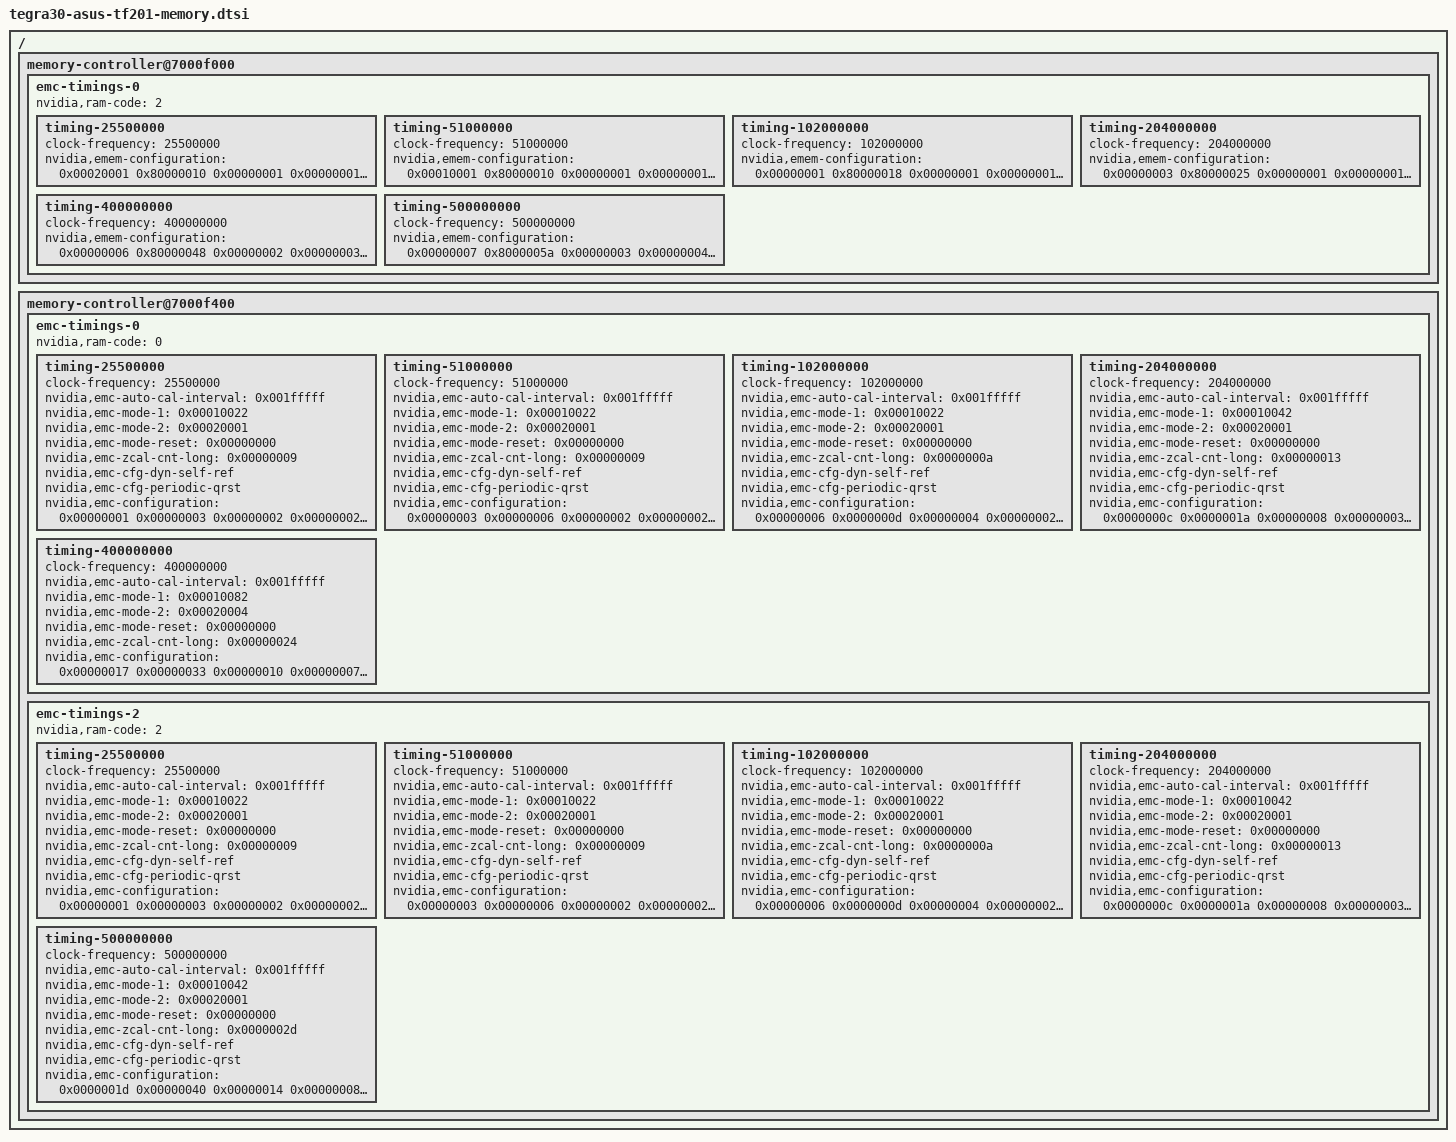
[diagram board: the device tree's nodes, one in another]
// SPDX-License-Identifier: GPL-2.0

/* This dtsi file describes TF201 memory layout, will be merged into tree */
/* It uses Elpida EDB8132B2MA-8D-F lpDDR2 and unspecified lpDDR2 500MHz */

/ {
	memory-controller@7000f000 {
		emc-timings-0 {
			/* EMEM timings are common */
			timing-25500000 {
				clock-frequency = <25500000>;

				nvidia,emem-configuration = < 0x00020001 0x80000010
						0x00000001 0x00000001 0x00000002 0x00000000
						0x00000003 0x00000001 0x00000002 0x00000004
						0x00000001 0x00000000 0x00000002 0x00000002
						0x02020001 0x00060402 0x73e30303 0x001f0000 >;
			};

			timing-51000000 {
				clock-frequency = <51000000>;

				nvidia,emem-configuration = < 0x00010001 0x80000010
						0x00000001 0x00000001 0x00000002 0x00000000
						0x00000003 0x00000001 0x00000002 0x00000004
						0x00000001 0x00000000 0x00000002 0x00000002
						0x02020001 0x00060402 0x72c30303 0x001f0000 >;
			};

			timing-102000000 {
				clock-frequency = <102000000>;

				nvidia,emem-configuration = < 0x00000001 0x80000018
						0x00000001 0x00000001 0x00000003 0x00000001
						0x00000003 0x00000001 0x00000002 0x00000004
						0x00000001 0x00000000 0x00000002 0x00000002
						0x02020001 0x00060403 0x72430504 0x001f0000 >;
			};

			timing-204000000 {
				clock-frequency = <204000000>;

				nvidia,emem-configuration = < 0x00000003 0x80000025
						0x00000001 0x00000001 0x00000006 0x00000003
						0x00000005 0x00000001 0x00000002 0x00000004
						0x00000001 0x00000000 0x00000003 0x00000002
						0x02030001 0x00070506 0x71e40a07 0x001f0000 >;
			};

/*
			nvidia,ram-code = <0>; /* Elpida 1GB EDB8132B2MA-8D-F lpDDR2 */
			timing-400000000 {
				clock-frequency = <400000000>;

				nvidia,emem-configuration = < 0x00000006 0x80000048
						0x00000002 0x00000003 0x0000000c 0x00000007
						0x00000009 0x00000001 0x00000002 0x00000006
						0x00000001 0x00000000 0x00000004 0x00000004
						0x04040001 0x000d090c 0x71c6120d 0x001f0000 >;
			};
*/

			nvidia,ram-code = <2>; /* Unknown vendor lpDDR2 500MHz */
			timing-500000000 {
				clock-frequency = <500000000>;

				nvidia,emem-configuration = < 0x00000007 0x8000005a
						0x00000003 0x00000004 0x0000000e 0x00000009
						0x0000000c 0x00000002 0x00000002 0x00000008
						0x00000001 0x00000000 0x00000004 0x00000005
						0x05040001 0x00100a0e 0x71c8170f 0x001f0000 >;
			};
		};
	};

	memory-controller@7000f400 {
		emc-timings-0 {
			/* Rev 3.1 with max frequency 400 MHz */
			nvidia,ram-code = <0>; /* Elpida 1GB EDB8132B2MA-8D-F lpDDR2 */

			timing-25500000 {
				clock-frequency = <25500000>;

				nvidia,emc-auto-cal-interval = <0x001fffff>;
				nvidia,emc-mode-1 = <0x00010022>;
				nvidia,emc-mode-2 = <0x00020001>;
				nvidia,emc-mode-reset = <0x00000000>;
				nvidia,emc-zcal-cnt-long = <0x00000009>;
				nvidia,emc-cfg-dyn-self-ref;
				nvidia,emc-cfg-periodic-qrst;

				nvidia,emc-configuration =  < 0x00000001 
						0x00000003 0x00000002 0x00000002 0x00000004
						0x00000004 0x00000001 0x00000005 0x00000002
						0x00000002 0x00000001 0x00000001 0x00000000
						0x00000001 0x00000003 0x00000001 0x0000000b
						0x0000000a 0x00000060 0x00000000 0x00000018
						0x00000001 0x00000001 0x00000002 0x00000000
						0x00000001 0x00000007 0x00000004 0x00000004
						0x00000003 0x00000008 0x00000004 0x00000004
						0x00000002 0x0000006b 0x00000004 0x00000004
						0x00000000 0x00000000 0x00004282 0x00780084
						0x00008000 0x00098000 0x00098000 0x00098000
						0x00098000 0x00000010 0x00000010 0x00000010
						0x00000010 0x00000000 0x00000000 0x00000000
						0x00000000 0x00000008 0x00000008 0x00000008
						0x00000008 0x00000000 0x00000000 0x00000000
						0x00000000 0x00000000 0x00000000 0x00000000
						0x00000000 0x00080000 0x00080000 0x00080000
						0x00080000 0x00100220 0x0800201c 0x00000000
						0x77ffc004 0x01f1f008 0x00000000 0x00000007
						0x08000068 0x08000000 0x00000802 0x00000000
						0x00000009 0x00090009 0xa0f10000 0x00000000
						0x00000000 0x800001c5 0xe0000000 0xff00ff00 >;
			};

			timing-51000000 {
				clock-frequency = <51000000>;

				nvidia,emc-auto-cal-interval = <0x001fffff>;
				nvidia,emc-mode-1 = <0x00010022>;
				nvidia,emc-mode-2 = <0x00020001>;
				nvidia,emc-mode-reset = <0x00000000>;
				nvidia,emc-zcal-cnt-long = <0x00000009>;
				nvidia,emc-cfg-dyn-self-ref;
				nvidia,emc-cfg-periodic-qrst;

				nvidia,emc-configuration =  < 0x00000003
						0x00000006 0x00000002 0x00000002 0x00000004
						0x00000004 0x00000001 0x00000005 0x00000002
						0x00000002 0x00000001 0x00000001 0x00000000
						0x00000001 0x00000003 0x00000001 0x0000000b
						0x0000000a 0x000000c0 0x00000000 0x00000030
						0x00000001 0x00000001 0x00000002 0x00000000
						0x00000001 0x00000007 0x00000008 0x00000008
						0x00000003 0x00000008 0x00000004 0x00000004
						0x00000002 0x000000d5 0x00000004 0x00000004
						0x00000000 0x00000000 0x00004282 0x00780084
						0x00008000 0x00098000 0x00098000 0x00098000
						0x00098000 0x00000010 0x00000010 0x00000010
						0x00000010 0x00000000 0x00000000 0x00000000
						0x00000000 0x00000018 0x00000018 0x00000018
						0x00000018 0x00000000 0x00000000 0x00000000
						0x00000000 0x00000000 0x00000000 0x00000000
						0x00000000 0x00080000 0x00080000 0x00080000
						0x00080000 0x00100220 0x0800201c 0x00000000
						0x77ffc004 0x01f1f008 0x00000000 0x00000007
						0x08000068 0x08000000 0x00000802 0x00000000
						0x00000009 0x00090009 0xa0f10000 0x00000000
						0x00000000 0x80000287 0xe0000000 0xff00ff00 >;
			};

			timing-102000000 {
				clock-frequency = <102000000>;

				nvidia,emc-auto-cal-interval = <0x001fffff>;
				nvidia,emc-mode-1 = <0x00010022>;
				nvidia,emc-mode-2 = <0x00020001>;
				nvidia,emc-mode-reset = <0x00000000>;
				nvidia,emc-zcal-cnt-long = <0x0000000a>;
				nvidia,emc-cfg-dyn-self-ref;
				nvidia,emc-cfg-periodic-qrst;

				nvidia,emc-configuration =  < 0x00000006
						0x0000000d 0x00000004 0x00000002 0x00000004
						0x00000004 0x00000001 0x00000005 0x00000002
						0x00000002 0x00000001 0x00000001 0x00000000
						0x00000001 0x00000003 0x00000001 0x0000000b
						0x0000000a 0x00000181 0x00000000 0x00000060
						0x00000001 0x00000001 0x00000002 0x00000000
						0x00000001 0x00000007 0x0000000f 0x0000000f
						0x00000003 0x00000008 0x00000004 0x00000004
						0x00000002 0x000001a9 0x00000004 0x00000006
						0x00000000 0x00000000 0x00004282 0x00780084
						0x00008000 0x000a0000 0x000a0000 0x000a0000
						0x000a0000 0x00000010 0x00000010 0x00000010
						0x00000010 0x00000000 0x00000000 0x00000000
						0x00000000 0x00000008 0x00000008 0x00000008
						0x00000008 0x00000000 0x00000000 0x00000000
						0x00000000 0x00000000 0x00000000 0x00000000
						0x00000000 0x00080000 0x00080000 0x00080000
						0x00080000 0x00120220 0x0800201c 0x00000000
						0x77ffc004 0x01f1f008 0x00000000 0x00000007
						0x08000068 0x08000000 0x00000802 0x00000000
						0x0000000a 0x00090009 0xa0f10000 0x00000000
						0x00000000 0x8000040b 0xe0000000 0xff00ff00 >;
			};

			timing-204000000 {
				clock-frequency = <204000000>;

				nvidia,emc-auto-cal-interval = <0x001fffff>;
				nvidia,emc-mode-1 = <0x00010042>;
				nvidia,emc-mode-2 = <0x00020001>;
				nvidia,emc-mode-reset = <0x00000000>;
				nvidia,emc-zcal-cnt-long = <0x00000013>;
				nvidia,emc-cfg-dyn-self-ref;
				nvidia,emc-cfg-periodic-qrst;

				nvidia,emc-configuration =  < 0x0000000c
						0x0000001a 0x00000008 0x00000003 0x00000005
						0x00000004 0x00000001 0x00000006 0x00000003
						0x00000003 0x00000002 0x00000002 0x00000000
						0x00000001 0x00000003 0x00000001 0x0000000c
						0x0000000a 0x00000303 0x00000000 0x000000c0
						0x00000001 0x00000001 0x00000003 0x00000000
						0x00000001 0x00000007 0x0000001d 0x0000001d
						0x00000004 0x0000000b 0x00000005 0x00000004
						0x00000002 0x00000351 0x00000004 0x00000006
						0x00000000 0x00000000 0x00004282 0x00440084
						0x00008000 0x00074000 0x00074000 0x00074000
						0x00074000 0x00000010 0x00000010 0x00000010
						0x00000010 0x00000000 0x00000000 0x00000000
						0x00000000 0x00000018 0x00000018 0x00000018
						0x00000018 0x00000000 0x00000000 0x00000000
						0x00000000 0x00000000 0x00000000 0x00000000
						0x00000000 0x00078000 0x00078000 0x00078000
						0x00078000 0x00100220 0x0800201c 0x00000000
						0x77ffc004 0x01f1f008 0x00000000 0x00000007
						0x08000068 0x08000000 0x00000802 0x00000000
						0x00000013 0x00090009 0xa0f10000 0x00000000
						0x00000000 0x80000713 0xe0000000 0xff00ff00 >;
			};

			timing-400000000 {
				clock-frequency = <400000000>;

				nvidia,emc-auto-cal-interval = <0x001fffff>;
				nvidia,emc-mode-1 = <0x00010082>;
				nvidia,emc-mode-2 = <0x00020004>;
				nvidia,emc-mode-reset = <0x00000000>;
				nvidia,emc-zcal-cnt-long = <0x00000024>;

				nvidia,emc-configuration =  < 0x00000017
						0x00000033 0x00000010 0x00000007 0x00000007
						0x00000007 0x00000002 0x0000000a 0x00000007
						0x00000007 0x00000003 0x00000002 0x00000000
						0x00000003 0x00000007 0x00000004 0x0000000d
						0x0000000e 0x000005e9 0x00000000 0x0000017a
						0x00000002 0x00000002 0x00000007 0x00000000
						0x00000001 0x0000000c 0x00000038 0x00000038
						0x00000006 0x00000014 0x00000009 0x00000004
						0x00000002 0x00000680 0x00000000 0x00000006
						0x00000000 0x00000000 0x00006282 0x001d0084
						0x00008000 0x0002c000 0x0002c000 0x0002c000
						0x0002c000 0x00000010 0x00000010 0x00000010
						0x00000010 0x00000000 0x00000000 0x00000000
						0x00000000 0x00000008 0x00000008 0x00000008
						0x00000008 0x00000000 0x00000000 0x00000000
						0x00000000 0x00000000 0x00000000 0x00000000
						0x00000000 0x00048000 0x00048000 0x00048000
						0x00048000 0x000c0220 0x0800003d 0x00000000
						0x77ffc004 0x01f1f408 0x00000000 0x00000007
						0x08000068 0x08000000 0x00000802 0x00000000
						0x00000024 0x000c000c 0xa0f10000 0x00000000
						0x00000000 0x80000ce6 0xe0000000 0xff00ff88 >;
			};
		};

		emc-timings-2 {
			/* Rev 3.2 with max frequency 500 MHz */
			nvidia,ram-code = <2>; /* Unknown vendor */

			timing-25500000 {
				clock-frequency = <25500000>;

				nvidia,emc-auto-cal-interval = <0x001fffff>;
				nvidia,emc-mode-1 = <0x00010022>;
				nvidia,emc-mode-2 = <0x00020001>;
				nvidia,emc-mode-reset = <0x00000000>;
				nvidia,emc-zcal-cnt-long = <0x00000009>;
				nvidia,emc-cfg-dyn-self-ref;
				nvidia,emc-cfg-periodic-qrst;

				nvidia,emc-configuration =  < 0x00000001 
						0x00000003 0x00000002 0x00000002 0x00000004
						0x00000004 0x00000001 0x00000005 0x00000002
						0x00000002 0x00000001 0x00000001 0x00000000
						0x00000001 0x00000003 0x00000001 0x0000000b
						0x00000009 0x00000060 0x00000000 0x00000018
						0x00000001 0x00000001 0x00000002 0x00000000
						0x00000001 0x00000007 0x00000004 0x00000004
						0x00000003 0x00000008 0x00000004 0x00000004
						0x00000002 0x0000006b 0x00000004 0x00000004
						0x00000000 0x00000000 0x00004282 0x00780084
						0x00008000 0x000fc000 0x000fc000 0x000fc000
						0x000fc000 0x000fc000 0x000fc000 0x000fc000
						0x000fc000 0x00000000 0x00000000 0x00000000
						0x00000000 0x00000000 0x00000000 0x00000000
						0x00000000 0x00000000 0x00000000 0x00000000
						0x00000000 0x00000000 0x00000000 0x00000000
						0x00000000 0x000fc000 0x000fc000 0x000fc000
						0x000fc000 0x00100220 0x0800201c 0x00000000
						0x77ffc004 0x01f1f008 0x00000000 0x00000007
						0x08000068 0x08000000 0x00000802 0x00064000
						0x0000000a 0x00090009 0xa0f10000 0x00000000
						0x00000000 0x800001c5 0xe0000000 0xff00ff00 >;
			};

			timing-51000000 {
				clock-frequency = <51000000>;

				nvidia,emc-auto-cal-interval = <0x001fffff>;
				nvidia,emc-mode-1 = <0x00010022>;
				nvidia,emc-mode-2 = <0x00020001>;
				nvidia,emc-mode-reset = <0x00000000>;
				nvidia,emc-zcal-cnt-long = <0x00000009>;
				nvidia,emc-cfg-dyn-self-ref;
				nvidia,emc-cfg-periodic-qrst;

				nvidia,emc-configuration =  < 0x00000003
						0x00000006 0x00000002 0x00000002 0x00000004
						0x00000004 0x00000001 0x00000005 0x00000002
						0x00000002 0x00000001 0x00000001 0x00000000
						0x00000001 0x00000003 0x00000001 0x0000000b
						0x00000009 0x000000c0 0x00000000 0x00000030
						0x00000001 0x00000001 0x00000002 0x00000000
						0x00000001 0x00000007 0x00000008 0x00000008
						0x00000003 0x00000008 0x00000004 0x00000004
						0x00000002 0x000000d5 0x00000004 0x00000004
						0x00000000 0x00000000 0x00004282 0x00780084
						0x00008000 0x000fc000 0x000fc000 0x000fc000
						0x000fc000 0x000fc000 0x000fc000 0x000fc000
						0x000fc000 0x00000000 0x00000000 0x00000000
						0x00000000 0x00000000 0x00000000 0x00000000
						0x00000000 0x00000000 0x00000000 0x00000000
						0x00000000 0x00000000 0x00000000 0x00000000
						0x00000000 0x000fc000 0x000fc000 0x000fc000
						0x000fc000 0x00100220 0x0800201c 0x00000000
						0x77ffc004 0x01f1f008 0x00000000 0x00000007
						0x08000068 0x08000000 0x00000802 0x00064000
						0x00000013 0x00090009 0xa0f10000 0x00000000
						0x00000000 0x80000287 0xe0000000 0xff00ff00 >;
			};

			timing-102000000 {
				clock-frequency = <102000000>;

				nvidia,emc-auto-cal-interval = <0x001fffff>;
				nvidia,emc-mode-1 = <0x00010022>;
				nvidia,emc-mode-2 = <0x00020001>;
				nvidia,emc-mode-reset = <0x00000000>;
				nvidia,emc-zcal-cnt-long = <0x0000000a>;
				nvidia,emc-cfg-dyn-self-ref;
				nvidia,emc-cfg-periodic-qrst;

				nvidia,emc-configuration =  < 0x00000006
						0x0000000d 0x00000004 0x00000002 0x00000004
						0x00000004 0x00000001 0x00000005 0x00000002
						0x00000002 0x00000001 0x00000001 0x00000000
						0x00000001 0x00000003 0x00000001 0x0000000b
						0x00000009 0x00000181 0x00000000 0x00000060
						0x00000001 0x00000001 0x00000002 0x00000000
						0x00000001 0x00000007 0x0000000f 0x0000000f
						0x00000003 0x00000008 0x00000004 0x00000004
						0x00000002 0x000001a9 0x00000004 0x00000004
						0x00000000 0x00000000 0x00004282 0x00780084
						0x00008000 0x000fc000 0x000fc000 0x000fc000
						0x000fc000 0x000fc000 0x000fc000 0x000fc000
						0x000fc000 0x00000000 0x00000000 0x00000000
						0x00000000 0x00000000 0x00000000 0x00000000
						0x00000000 0x00000000 0x00000000 0x00000000
						0x00000000 0x00000000 0x00000000 0x00000000
						0x00000000 0x000fc000 0x000fc000 0x000fc000
						0x000fc000 0x00100220 0x0800201c 0x00000000
						0x77ffc004 0x01f1f008 0x00000000 0x00000007
						0x08000068 0x08000000 0x00000802 0x00064000
						0x00000025 0x00090009 0xa0f10000 0x00000000
						0x00000000 0x8000040b 0xe0000000 0xff00ff00 >;
			};

			timing-204000000 {
				clock-frequency = <204000000>;

				nvidia,emc-auto-cal-interval = <0x001fffff>;
				nvidia,emc-mode-1 = <0x00010042>;
				nvidia,emc-mode-2 = <0x00020001>;
				nvidia,emc-mode-reset = <0x00000000>;
				nvidia,emc-zcal-cnt-long = <0x00000013>;
				nvidia,emc-cfg-dyn-self-ref;
				nvidia,emc-cfg-periodic-qrst;

				nvidia,emc-configuration =  < 0x0000000c
						0x0000001a 0x00000008 0x00000003 0x00000005
						0x00000004 0x00000001 0x00000006 0x00000003
						0x00000003 0x00000002 0x00000002 0x00000000
						0x00000001 0x00000003 0x00000001 0x0000000c
						0x0000000a 0x00000303 0x00000000 0x000000c0
						0x00000001 0x00000001 0x00000003 0x00000000
						0x00000001 0x00000007 0x0000001d 0x0000001d
						0x00000004 0x0000000b 0x00000005 0x00000004
						0x00000002 0x00000351 0x00000004 0x00000006
						0x00000000 0x00000000 0x00004282 0x00440084
						0x00008000 0x00060000 0x00060000 0x00060000
						0x00060000 0x00072000 0x00072000 0x00072000
						0x00072000 0x00000000 0x00000000 0x00000000
						0x00000000 0x00000000 0x00000000 0x00000000
						0x00000000 0x00000000 0x00000000 0x00000000
						0x00000000 0x00000000 0x00000000 0x00000000
						0x00000000 0x000d0000 0x000d0000 0x000d0000
						0x000d0000 0x000e0220 0x0800201c 0x00000000
						0x77ffc004 0x01f1f008 0x00000000 0x00000007
						0x08000068 0x08000000 0x00000802 0x00064000
						0x0000004a 0x00090009 0xa0f10000 0x00000000
						0x00000000 0x80000713 0xe0000000 0xff00ff00 >;
			};

			timing-500000000 {
				clock-frequency = <500000000>;

				nvidia,emc-auto-cal-interval = <0x001fffff>;
				nvidia,emc-mode-1 = <0x00010042>;
				nvidia,emc-mode-2 = <0x00020001>;
				nvidia,emc-mode-reset = <0x00000000>;
				nvidia,emc-zcal-cnt-long = <0x0000002d>;
				nvidia,emc-cfg-dyn-self-ref;
				nvidia,emc-cfg-periodic-qrst;

				nvidia,emc-configuration =  < 0x0000001d 
						0x00000040 0x00000014 0x00000008 0x00000007
						0x00000009 0x00000003 0x0000000d 0x00000008
						0x00000008 0x00000004 0x00000002 0x00000000
						0x00000004 0x00000008 0x00000005 0x0000000d
						0x0000000f 0x00000763 0x00000000 0x000001d8
						0x00000003 0x00000003 0x00000008 0x00000000
						0x00000001 0x0000000e 0x00000046 0x00000046
						0x00000008 0x00000019 0x0000000b 0x00000004
						0x00000002 0x00000820 0x00000000 0x00000006
						0x00000000 0x00000000 0x00006282 0xf0140091
						0x00008000 0x00000008 0x00000008 0x00000008
						0x00000008 0x0000000a 0x0000000a 0x0000000a
						0x0000000a 0x00000000 0x00000000 0x00000000
						0x00000000 0x00000000 0x00000000 0x00000000
						0x00000000 0x00000000 0x00000000 0x00000000
						0x00000000 0x00000000 0x00000000 0x00000000
						0x00000000 0x0000000c 0x0000000c 0x0000000c
						0x0000000c 0x00080220 0x0800003d 0x00000000
						0x77ffc004 0x01f1f408 0x00000000 0x00000007
						0x08000068 0x08000000 0x00000802 0x00064000
						0x000000b4 0x000d000d 0xa0f10404 0x00000000
						0x00000000 0x80000fde 0xe0000000 0xff00ff88 >;
			};
		};
	};
};
